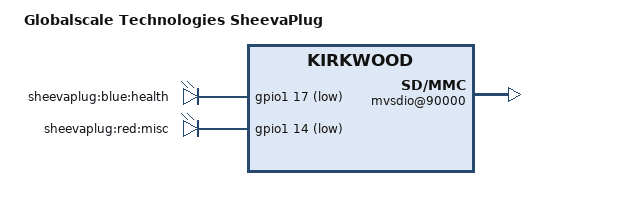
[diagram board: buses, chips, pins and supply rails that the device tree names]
/*
 * kirkwood-sheevaplug-esata.dts - Device tree file for Sheevaplug
 *
 * Copyright (C) 2013 Simon Baatz <gmbnomis@gmail.com>
 *
 * Licensed under GPLv2
 */

/dts-v1/;

/include/ "kirkwood-sheevaplug-common.dtsi"

/ {
	model = "Globalscale Technologies SheevaPlug";
	compatible = "globalscale,sheevaplug", "marvell,kirkwood-88f6281", "marvell,kirkwood";

	ocp@f1000000 {
		mvsdio@90000 {
			pinctrl-0 = <&pmx_sdio>;
			pinctrl-names = "default";
			status = "okay";
			/* No CD or WP GPIOs */
			broken-cd;
		};
	};

	gpio-leds {
		compatible = "gpio-leds";
		pinctrl-0 = <&pmx_led_blue &pmx_led_red>;
		pinctrl-names = "default";

		health {
			label = "sheevaplug:blue:health";
			gpios = <&gpio1 17 1>;
			linux,default-trigger = "default-on";
		};

		misc {
			label = "sheevaplug:red:misc";
			gpios = <&gpio1 14 1>;
		};
	};
};
